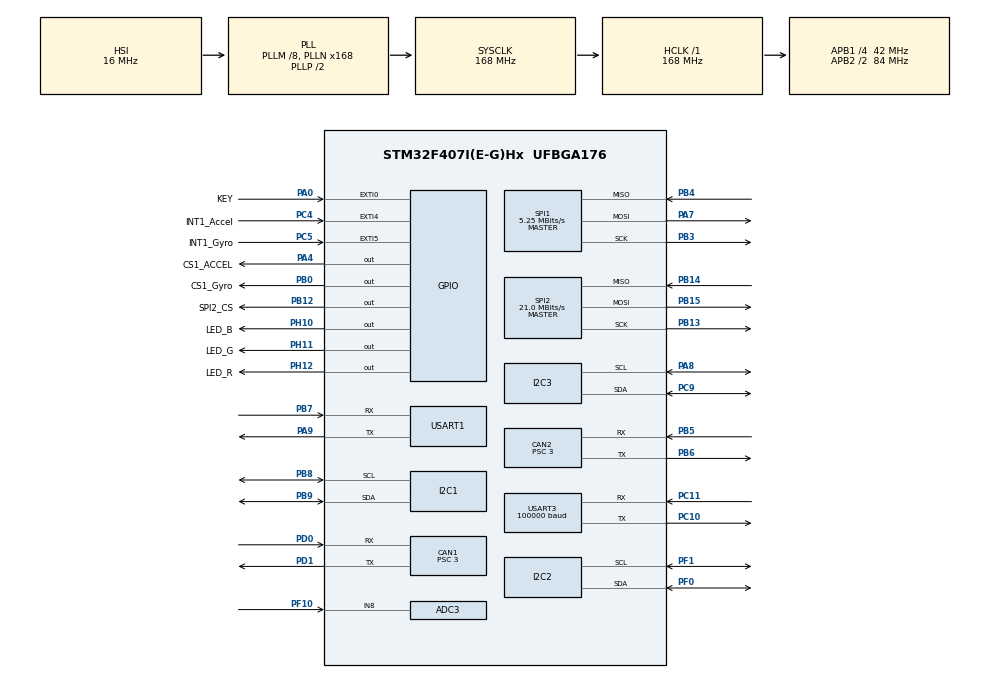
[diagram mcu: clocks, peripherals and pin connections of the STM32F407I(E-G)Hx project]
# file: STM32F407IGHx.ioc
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ADC3.Channel-0\#ChannelRegularConversion=ADC_CHANNEL_8
ADC3.NbrOfConversionFlag=1
ADC3.Rank-0\#ChannelRegularConversion=1
ADC3.SamplingTime-0\#ChannelRegularConversion=ADC_SAMPLETIME_3CYCLES
CAN1.BS1=CAN_BS1_9TQ
CAN1.BS2=CAN_BS2_4TQ
CAN1.CalculateBaudRate=1000000
CAN1.CalculateTimeBit=1000
CAN1.CalculateTimeQuantum=71.42857142857143
CAN1.Prescaler=3
CAN2.BS1=CAN_BS1_9TQ
CAN2.BS2=CAN_BS2_4TQ
CAN2.CalculateBaudRate=1000000
CAN2.CalculateTimeBit=1000
CAN2.CalculateTimeQuantum=71.42857142857143
CAN2.Prescaler=3
Dma.Request0=USART3_RX
Dma.USART3_RX.0.Direction=DMA_PERIPH_TO_MEMORY
Dma.USART3_RX.0.FIFOMode=DMA_FIFOMODE_DISABLE
Dma.USART3_RX.0.Instance=DMA1_Stream1
Dma.USART3_RX.0.MemDataAlignment=DMA_MDATAALIGN_BYTE
Dma.USART3_RX.0.MemInc=DMA_MINC_ENABLE
Dma.USART3_RX.0.Mode=DMA_NORMAL
Dma.USART3_RX.0.PeriphDataAlignment=DMA_PDATAALIGN_BYTE
Dma.USART3_RX.0.PeriphInc=DMA_PINC_DISABLE
Dma.USART3_RX.0.Priority=DMA_PRIORITY_LOW
FREERTOS.Tasks01=InitTask,40,128,_InitTask,As weak,NULL,Static,InitTaskBuffer,InitTaskControlBlock;GimbalTask,8,128,_GimbalTask,As weak,NULL,Static,GimbalTaskBuffer,GimbalTaskControlBlock;ChassisTask,8,128,_ChassisTask,As weak,NULL,Static,ChassisTaskBuffer,ChassisTaskControlBlock;GyroTask,8,128,_GyroTask,As weak,NULL,Static,GyroTaskBuffer,GyroTaskControlBlock;ControllerTask,9,128,_ControllerTask,As weak,NULL,Static,ChontrollerTaskBuffer,ChontrollerTaskControlBlock
FREERTOS.configUSE_NEWLIB_REENTRANT=1
Mcu.Family=STM32F4
Mcu.Name=STM32F407I(E-G)Hx
Mcu.Package=UFBGA176
NVIC.CAN1_RX0_IRQn=true\:5\:0\:false\:false\:true\:true\:true\:true\:true
NVIC.CAN1_TX_IRQn=true\:5\:0\:false\:false\:true\:true\:true\:true\:true
NVIC.DMA1_Stream1_IRQn=true\:5\:0\:false\:false\:true\:true\:false\:true\:true
NVIC.PriorityGroup=NVIC_PRIORITYGROUP_4
NVIC.TIM2_IRQn=true\:5\:0\:false\:false\:true\:true\:true\:true\:true
NVIC.TIM8_TRG_COM_TIM14_IRQn=true\:15\:0\:false\:false\:true\:false\:false\:true\:true
NVIC.TimeBase=TIM8_TRG_COM_TIM14_IRQn
NVIC.TimeBaseIP=TIM14
NVIC.USART3_IRQn=true\:5\:0\:false\:false\:true\:true\:true\:true\:true
PA0-WKUP.GPIO_Label=KEY
PA0-WKUP.Signal=GPXTI0
PA13.Mode=Serial_Wire
PA13.Signal=SYS_JTMS-SWDIO
PA14.Mode=Serial_Wire
PA14.Signal=SYS_JTCK-SWCLK
PA4.GPIO_Label=CS1_ACCEL
PA4.PinState=GPIO_PIN_SET
PA4.Signal=GPIO_Output
PA7.Mode=Full_Duplex_Master
PA7.Signal=SPI1_MOSI
PA8.Mode=I2C
PA8.Signal=I2C3_SCL
PA9.Mode=Asynchronous
PA9.Signal=USART1_TX
PB0.GPIO_Label=CS1_Gyro
PB0.PinState=GPIO_PIN_SET
PB0.Signal=GPIO_Output
PB12.GPIO_Label=SPI2_CS
PB12.Signal=GPIO_Output
PB13.Mode=Full_Duplex_Master
PB13.Signal=SPI2_SCK
PB14.Mode=Full_Duplex_Master
PB14.Signal=SPI2_MISO
PB15.Mode=Full_Duplex_Master
PB15.Signal=SPI2_MOSI
PB3.Mode=Full_Duplex_Master
PB3.Signal=SPI1_SCK
PB4.Mode=Full_Duplex_Master
PB4.Signal=SPI1_MISO
PB5.Mode=CAN_Activate
PB5.Signal=CAN2_RX
PB6.Mode=CAN_Activate
PB6.Signal=CAN2_TX
PB7.Mode=Asynchronous
PB7.Signal=USART1_RX
PB8.Mode=I2C
PB8.Signal=I2C1_SCL
PB9.Mode=I2C
PB9.Signal=I2C1_SDA
PC10.Mode=Asynchronous
PC10.Signal=USART3_TX
PC11.Mode=Asynchronous
PC11.Signal=USART3_RX
PC4.GPIO_Label=INT1_Accel
PC4.Signal=GPXTI4
PC5.GPIO_Label=INT1_Gyro
PC5.Signal=GPXTI5
PC9.Mode=I2C
PC9.Signal=I2C3_SDA
PD0.Mode=CAN_Activate
PD0.Signal=CAN1_RX
PD1.Mode=CAN_Activate
PD1.Signal=CAN1_TX
PF0.Mode=I2C
PF0.Signal=I2C2_SDA
PF1.Mode=I2C
PF1.Signal=I2C2_SCL
PF10.Mode=IN8
PF10.Signal=ADC3_IN8
PH0-OSC_IN.Mode=HSE-External-Oscillator
PH0-OSC_IN.Signal=RCC_OSC_IN
PH1-OSC_OUT.Mode=HSE-External-Oscillator
PH1-OSC_OUT.Signal=RCC_OSC_OUT
PH10.GPIO_Label=LED_B
PH10.Signal=GPIO_Output
PH11.GPIO_Label=LED_G
PH11.Signal=GPIO_Output
PH12.GPIO_Label=LED_R
PH12.Signal=GPIO_Output
ProjectManager.HeapSize=0x2000
ProjectManager.StackSize=0x2000
ProjectManager.TargetToolchain=STM32CubeIDE
RCC.48MHZClocksFreq_Value=84000000
RCC.AHBFreq_Value=168000000
RCC.APB1CLKDivider=RCC_HCLK_DIV4
RCC.APB1Freq_Value=42000000
RCC.APB1TimFreq_Value=84000000
RCC.APB2CLKDivider=RCC_HCLK_DIV2
RCC.APB2Freq_Value=84000000
RCC.APB2TimFreq_Value=168000000
RCC.CortexFreq_Value=168000000
RCC.HCLKFreq_Value=168000000
RCC.HSE_VALUE=12000000
RCC.HSI_VALUE=16000000
RCC.LSE_VALUE=32768
RCC.PLLM=8
RCC.PLLN=168
RCC.SYSCLKFreq_VALUE=168000000
RCC.SYSCLKSource=RCC_SYSCLKSOURCE_PLLCLK
RCC.VCOOutputFreq_Value=336000000
SPI1.BaudRatePrescaler=SPI_BAUDRATEPRESCALER_16
SPI1.CLKPhase=SPI_PHASE_2EDGE
SPI1.CalculateBaudRate=5.25 MBits/s
SPI1.Direction=SPI_DIRECTION_2LINES
SPI1.Mode=SPI_MODE_MASTER
SPI1.VirtualType=VM_MASTER
SPI2.CalculateBaudRate=21.0 MBits/s
SPI2.Direction=SPI_DIRECTION_2LINES
SPI2.Mode=SPI_MODE_MASTER
SPI2.VirtualType=VM_MASTER
TIM2.AutoReloadPreload=TIM_AUTORELOAD_PRELOAD_DISABLE
TIM2.Period=84-1
TIM2.Prescaler=0
USART1.VirtualMode=VM_ASYNC
USART3.BaudRate=100000
USART3.StopBits=STOPBITS_1
USART3.VirtualMode=VM_ASYNC
USART3.WordLength=WORDLENGTH_9B
VP_FREERTOS_VS_CMSIS_V2.Mode=CMSIS_V2
VP_SYS_VS_tim14.Mode=TIM14
VP_TIM2_VS_ClockSourceINT.Mode=Internal
board=custom

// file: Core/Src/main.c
/* USER CODE BEGIN Header */
/**
  ******************************************************************************
  * @file           : main.c
  * @brief          : Main program body
  ******************************************************************************
  * @attention
  *
  * Copyright (c) 2023 STMicroelectronics.
  * All rights reserved.
  *
  * This software is licensed under terms that can be found in the LICENSE file
  * in the root directory of this software component.
  * If no LICENSE file comes with this software, it is provided AS-IS.
  *
  ******************************************************************************
  */
/* USER CODE END Header */
#include "main.h"
#include "cmsis_os.h"
#include "adc.h"
#include "can.h"
#include "dma.h"
#include "i2c.h"
#include "spi.h"
#include "tim.h"
#include "usart.h"
#include "gpio.h"

/* USER CODE BEGIN Includes */
// #include "usr_main.h"
/* USER CODE END Includes */

void SystemClock_Config(void);
void MX_FREERTOS_Init(void);

int main(void)
{

  /* MCU Configuration--------------------------------------------------------*/

  /* Reset of all peripherals, Initializes the Flash interface and the Systick. */
  HAL_Init();

  /* Configure the system clock */
  SystemClock_Config();

  /* Initialize all configured peripherals */
  MX_GPIO_Init();
  MX_DMA_Init();
  MX_ADC3_Init();
  MX_CAN1_Init();
  MX_CAN2_Init();
  MX_I2C1_Init();
  MX_I2C2_Init();
  MX_I2C3_Init();
  MX_SPI1_Init();
  MX_SPI2_Init();
  MX_USART1_UART_Init();
  MX_USART3_UART_Init();
  MX_TIM2_Init();
  /* USER CODE BEGIN 2 */
  // return usr_main();
  /* USER CODE END 2 */

  /* Init scheduler */
  osKernelInitialize();  /* Call init function for freertos objects (in freertos.c) */
  MX_FREERTOS_Init();

  /* Start scheduler */
  osKernelStart();

  /* We should never get here as control is now taken by the scheduler */
  /* Infinite loop */
  while (1)
  {

  }
}

void SystemClock_Config(void)
{
  RCC_OscInitTypeDef RCC_OscInitStruct = {0};
  RCC_ClkInitTypeDef RCC_ClkInitStruct = {0};

  /** Configure the main internal regulator output voltage
  */
  __HAL_RCC_PWR_CLK_ENABLE();
  __HAL_PWR_VOLTAGESCALING_CONFIG(PWR_REGULATOR_VOLTAGE_SCALE1);

  /** Initializes the RCC Oscillators according to the specified parameters
  * in the RCC_OscInitTypeDef structure.
  */
  RCC_OscInitStruct.OscillatorType = RCC_OSCILLATORTYPE_HSI;
  RCC_OscInitStruct.HSIState = RCC_HSI_ON;
  RCC_OscInitStruct.HSICalibrationValue = RCC_HSICALIBRATION_DEFAULT;
  RCC_OscInitStruct.PLL.PLLState = RCC_PLL_ON;
  RCC_OscInitStruct.PLL.PLLSource = RCC_PLLSOURCE_HSI;
  RCC_OscInitStruct.PLL.PLLM = 8;
  RCC_OscInitStruct.PLL.PLLN = 168;
  RCC_OscInitStruct.PLL.PLLP = RCC_PLLP_DIV2;
  RCC_OscInitStruct.PLL.PLLQ = 4;
  if (HAL_RCC_OscConfig(&RCC_OscInitStruct) != HAL_OK)
  {
    Error_Handler();
  }

  /** Initializes the CPU, AHB and APB buses clocks
  */
  RCC_ClkInitStruct.ClockType = RCC_CLOCKTYPE_HCLK|RCC_CLOCKTYPE_SYSCLK
                              |RCC_CLOCKTYPE_PCLK1|RCC_CLOCKTYPE_PCLK2;
  RCC_ClkInitStruct.SYSCLKSource = RCC_SYSCLKSOURCE_PLLCLK;
  RCC_ClkInitStruct.AHBCLKDivider = RCC_SYSCLK_DIV1;
  RCC_ClkInitStruct.APB1CLKDivider = RCC_HCLK_DIV4;
  RCC_ClkInitStruct.APB2CLKDivider = RCC_HCLK_DIV2;

  if (HAL_RCC_ClockConfig(&RCC_ClkInitStruct, FLASH_LATENCY_5) != HAL_OK)
  {
    Error_Handler();
  }
}

void HAL_TIM_PeriodElapsedCallback(TIM_HandleTypeDef *htim)
{
  if (htim->Instance == TIM14) {
    HAL_IncTick();
  }
}

void Error_Handler(void)
{
  __disable_irq();
  while (1)
  {
  }
}

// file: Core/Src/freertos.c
/* USER CODE BEGIN Header */
/**
  ******************************************************************************
  * File Name          : freertos.c
  * Description        : Code for freertos applications
  ******************************************************************************
  * @attention
  *
  * Copyright (c) 2023 STMicroelectronics.
  * All rights reserved.
  *
  * This software is licensed under terms that can be found in the LICENSE file
  * in the root directory of this software component.
  * If no LICENSE file comes with this software, it is provided AS-IS.
  *
  ******************************************************************************
  */
/* USER CODE END Header */

#include "FreeRTOS.h"
#include "task.h"
#include "main.h"
#include "cmsis_os.h"

typedef StaticTask_t osStaticThreadDef_t;

/* Definitions for InitTask */
osThreadId_t InitTaskHandle;
uint32_t InitTaskBuffer[ 128 ];
osStaticThreadDef_t InitTaskControlBlock;
const osThreadAttr_t InitTask_attributes = {
  .name = "InitTask",
  .cb_mem = &InitTaskControlBlock,
  .cb_size = sizeof(InitTaskControlBlock),
  .stack_mem = &InitTaskBuffer[0],
  .stack_size = sizeof(InitTaskBuffer),
  .priority = (osPriority_t) osPriorityHigh,
};
/* Definitions for GimbalTask */
osThreadId_t GimbalTaskHandle;
uint32_t GimbalTaskBuffer[ 128 ];
osStaticThreadDef_t GimbalTaskControlBlock;
const osThreadAttr_t GimbalTask_attributes = {
  .name = "GimbalTask",
  .cb_mem = &GimbalTaskControlBlock,
  .cb_size = sizeof(GimbalTaskControlBlock),
  .stack_mem = &GimbalTaskBuffer[0],
  .stack_size = sizeof(GimbalTaskBuffer),
  .priority = (osPriority_t) osPriorityLow,
};
/* Definitions for ChassisTask */
osThreadId_t ChassisTaskHandle;
uint32_t ChassisTaskBuffer[ 128 ];
osStaticThreadDef_t ChassisTaskControlBlock;
const osThreadAttr_t ChassisTask_attributes = {
  .name = "ChassisTask",
  .cb_mem = &ChassisTaskControlBlock,
  .cb_size = sizeof(ChassisTaskControlBlock),
  .stack_mem = &ChassisTaskBuffer[0],
  .stack_size = sizeof(ChassisTaskBuffer),
  .priority = (osPriority_t) osPriorityLow,
};
/* Definitions for GyroTask */
osThreadId_t GyroTaskHandle;
uint32_t GyroTaskBuffer[ 128 ];
osStaticThreadDef_t GyroTaskControlBlock;
const osThreadAttr_t GyroTask_attributes = {
  .name = "GyroTask",
  .cb_mem = &GyroTaskControlBlock,
  .cb_size = sizeof(GyroTaskControlBlock),
  .stack_mem = &GyroTaskBuffer[0],
  .stack_size = sizeof(GyroTaskBuffer),
  .priority = (osPriority_t) osPriorityLow,
};
/* Definitions for ControllerTask */
osThreadId_t ControllerTaskHandle;
uint32_t ChontrollerTaskBuffer[ 128 ];
osStaticThreadDef_t ChontrollerTaskControlBlock;
const osThreadAttr_t ControllerTask_attributes = {
  .name = "ControllerTask",
  .cb_mem = &ChontrollerTaskControlBlock,
  .cb_size = sizeof(ChontrollerTaskControlBlock),
  .stack_mem = &ChontrollerTaskBuffer[0],
  .stack_size = sizeof(ChontrollerTaskBuffer),
  .priority = (osPriority_t) osPriorityLow1,
};

void _InitTask(void *argument);
void _GimbalTask(void *argument);
void _ChassisTask(void *argument);
void _GyroTask(void *argument);
void _ControllerTask(void *argument);

void MX_FREERTOS_Init(void); /* (MISRA C 2004 rule 8.1) */

void MX_FREERTOS_Init(void) {

  /* Create the thread(s) */
  /* creation of InitTask */
  InitTaskHandle = osThreadNew(_InitTask, NULL, &InitTask_attributes);

  /* creation of GimbalTask */
  GimbalTaskHandle = osThreadNew(_GimbalTask, NULL, &GimbalTask_attributes);

  /* creation of ChassisTask */
  ChassisTaskHandle = osThreadNew(_ChassisTask, NULL, &ChassisTask_attributes);

  /* creation of GyroTask */
  GyroTaskHandle = osThreadNew(_GyroTask, NULL, &GyroTask_attributes);

  /* creation of ControllerTask */
  ControllerTaskHandle = osThreadNew(_ControllerTask, NULL, &ControllerTask_attributes);

}

__weak void _InitTask(void *argument)
{
  for(;;)
  {
    osDelay(1);
  }
}

__weak void _GimbalTask(void *argument)
{
  for(;;)
  {
    osDelay(1);
  }
}

__weak void _ChassisTask(void *argument)
{
  for(;;)
  {
    osDelay(1);
  }
}

__weak void _GyroTask(void *argument)
{
  for(;;)
  {
    osDelay(1);
  }
}

__weak void _ControllerTask(void *argument)
{
  for(;;)
  {
    osDelay(1);
  }
}
